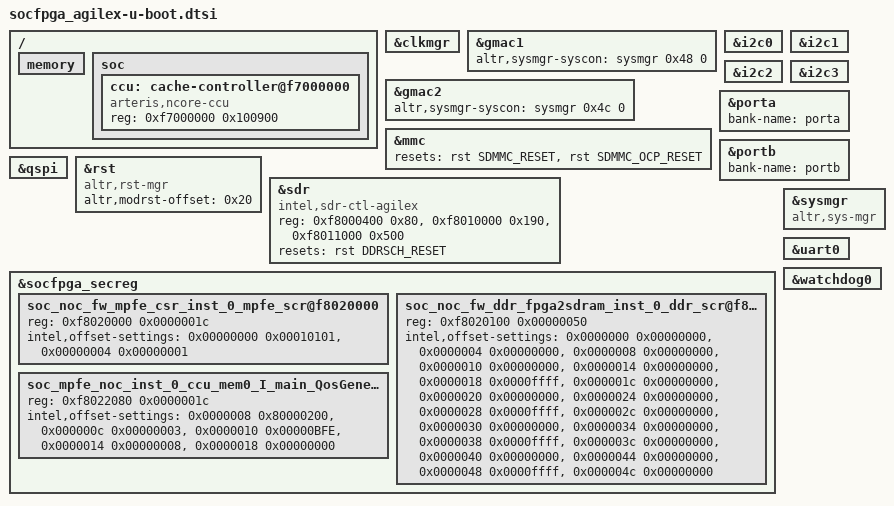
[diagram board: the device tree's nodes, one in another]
// SPDX-License-Identifier: GPL-2.0+
/*
 * U-Boot additions
 *
 * Copyright (C) 2019-2022 Intel Corporation <www.intel.com>
 */

#include "socfpga_soc64_u-boot.dtsi"
#include "socfpga_soc64_fit-u-boot.dtsi"

/{
	memory {
		#address-cells = <2>;
		#size-cells = <2>;
		bootph-all;
	};

	soc {
		bootph-all;

		ccu: cache-controller@f7000000 {
			compatible = "arteris,ncore-ccu";
			reg = <0xf7000000 0x100900>;
			bootph-all;
		};
	};
};

&clkmgr {
	bootph-all;
};

&gmac1 {
	altr,sysmgr-syscon = <&sysmgr 0x48 0>;
};

&gmac2 {
	altr,sysmgr-syscon = <&sysmgr 0x4c 0>;
};

&i2c0 {
	reset-names = "i2c";
};

&i2c1 {
	reset-names = "i2c";
};

&i2c2 {
	reset-names = "i2c";
};

&i2c3 {
	reset-names = "i2c";
};

&mmc {
	resets = <&rst SDMMC_RESET>, <&rst SDMMC_OCP_RESET>;
};

&porta {
	bank-name = "porta";
};

&portb {
	bank-name = "portb";
};

&qspi {
	bootph-all;
};

&rst {
	compatible = "altr,rst-mgr";
	altr,modrst-offset = <0x20>;
	bootph-all;
};

&sdr {
	compatible = "intel,sdr-ctl-agilex";
	reg = <0xf8000400 0x80>,
	      <0xf8010000 0x190>,
	      <0xf8011000 0x500>;
	resets = <&rst DDRSCH_RESET>;
	bootph-all;
};

&socfpga_secreg {
	soc_noc_fw_mpfe_csr_inst_0_mpfe_scr@f8020000 {
		reg = <0xf8020000 0x0000001c>;
		intel,offset-settings =
			/* Disable MPFE firewall for SMMU */
			<0x00000000 0x00010101>,
			/* Disable MPFE firewall for HMC adapter */
			<0x00000004 0x00000001>;
		bootph-all;
	};

	/*
	 * Below are all fpga2sdram firewall settings with default
	 * reset value for the sake of easy reference by users.
	 * Users may choose to remove any of these register
	 * configurations that they do not require in their specific
	 * implementation.
	 */
	soc_noc_fw_ddr_fpga2sdram_inst_0_ddr_scr@f8020100 {
		reg = <0xf8020100 0x00000050>;
		intel,offset-settings =
			<0x0000000 0x00000000>,
			<0x0000004 0x00000000>,
			<0x0000008 0x00000000>,
			<0x0000010 0x00000000>,
			<0x0000014 0x00000000>,
			<0x0000018 0x0000ffff>,
			<0x000001c 0x00000000>,
			<0x0000020 0x00000000>,
			<0x0000024 0x00000000>,
			<0x0000028 0x0000ffff>,
			<0x000002c 0x00000000>,
			<0x0000030 0x00000000>,
			<0x0000034 0x00000000>,
			<0x0000038 0x0000ffff>,
			<0x000003c 0x00000000>,
			<0x0000040 0x00000000>,
			<0x0000044 0x00000000>,
			<0x0000048 0x0000ffff>,
			<0x000004c 0x00000000>;
		bootph-all;
	};

	/*
	 * Example of ccu_mem0_I_main QOS settings with
	 * default reset value for the sake of easy reference
	 * by users. Users may choose to remove any of these register
	 * configurations that they do not require in their specific
	 * implementation.
	 */
	soc_mpfe_noc_inst_0_ccu_mem0_I_main_QosGenerator@f8022080 {
		reg = <0xf8022080 0x0000001c>;
		intel,offset-settings =
			<0x0000008 0x80000200>,
			<0x000000c 0x00000003>,
			<0x0000010 0x00000BFE>,
			<0x0000014 0x00000008>,
			<0x0000018 0x00000000>;
		bootph-all;
	};
};

&sysmgr {
	compatible = "altr,sys-mgr", "syscon";
	bootph-all;
};

&uart0 {
	bootph-all;
};

&watchdog0 {
	bootph-all;
};
